# SYSCTRL_PADCONF_CORE register map
Vendor: Texas Instruments
Peripheral module from a debugger description file (folder omap4460).
Registers are 32-bit, access per field, reset 0x10F010F unless marked. A register's access mark holds for its fields unless they carry their own. Offsets are as the file gives them; lines under a group give offsets from that group; [hi:lo] are bit positions; {n}, {i} and the like mark numbered series; 'fields as' and 'values as' point back to an identical list; <NAME> marks a mode.

## SYSCTRL_PADCONF_CORE (part 1 of 10)
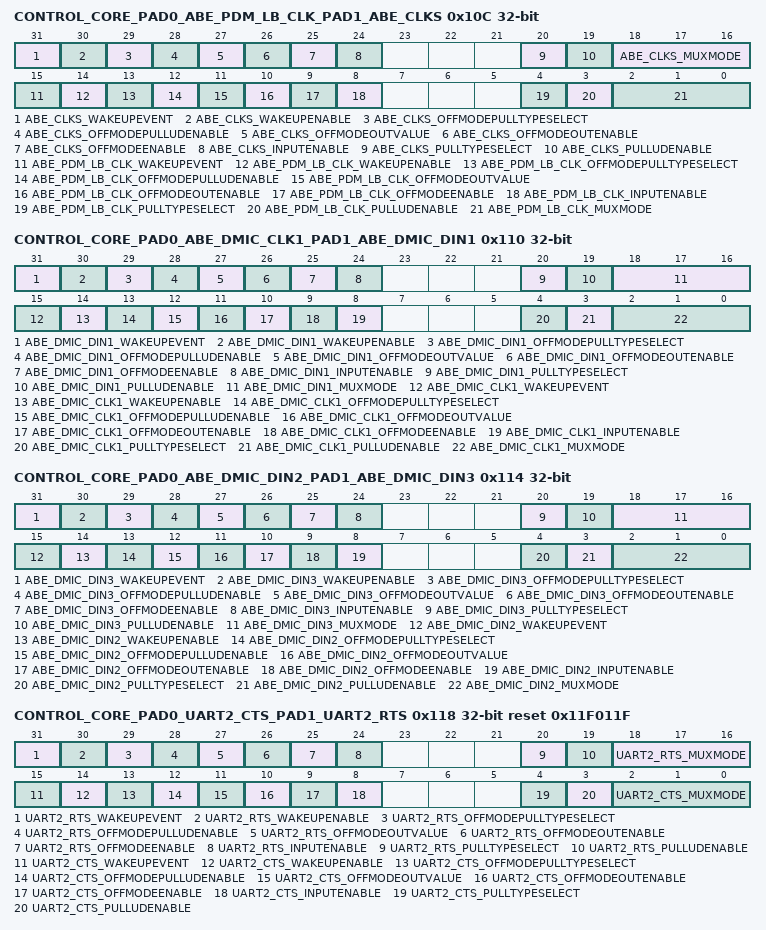
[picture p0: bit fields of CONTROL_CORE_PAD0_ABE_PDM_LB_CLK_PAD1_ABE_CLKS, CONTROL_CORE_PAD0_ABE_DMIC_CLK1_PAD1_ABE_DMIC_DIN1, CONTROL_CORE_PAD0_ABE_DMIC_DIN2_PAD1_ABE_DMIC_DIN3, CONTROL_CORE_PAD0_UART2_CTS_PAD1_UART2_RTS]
0x10C CONTROL_CORE_PAD0_ABE_PDM_LB_CLK_PAD1_ABE_CLKS — Register control for Pads abe_pdm_lb_clk and abe_clks Access conditions. Read: unrestricted, Write: unrestricted
  [31] ABE_CLKS_WAKEUPEVENT ro — Pad_x wake-up event status latched in the IO
    0=ABE_CLKS_WAKEUPEVENT_0_r (No wake-up event occurred); 1=ABE_CLKS_WAKEUPEVENT_1_r (A wake-up event occurred)
  [30] ABE_CLKS_WAKEUPENABLE rw — Input pad wake-up enable (and OFF mode input enable value)
    0=wake-up detection is disabled; 1=wake-up detection is enabled
  [29] ABE_CLKS_OFFMODEPULLTYPESELECT rw — OffMode mode pullup/down selection for pad abe_clks
    0=Offmode pulldown selected; 1=Offmode pullup selected
  [28] ABE_CLKS_OFFMODEPULLUDENABLE rw — OffMode mode pullup/down enable for pad abe_clks
    0=Offmode pullup/down disabled; 1=Offmode pullup/down enabled
  [27] ABE_CLKS_OFFMODEOUTVALUE rw — OffMode mode output value for pad abe_clks
    0=Set value at 0; 1=Set value at 1
  [26] ABE_CLKS_OFFMODEOUTENABLE rw — OffMode mode output enable value for pad abe_clks. This is an active low signal
    0=Output enable; 1=Output disable
  [25] ABE_CLKS_OFFMODEENABLE rw — OffMode mode override control for pad abe_clks
    0=I/O state keeps its previous state when OFF mode is active; 1=I/O state is forced to OFF mode value when OFF mode is active
  [24] ABE_CLKS_INPUTENABLE rw — Input enable value for pad abe_clks
    0=Input buffer of I/O cell is disabled; 1=Input buffer of I/O cell is enabled
  [20] ABE_CLKS_PULLTYPESELECT rw — pullup/down selection for pad abe_clks
    0=pulldown selected; 1=pullup selected
  [19] ABE_CLKS_PULLUDENABLE rw — pullup/down enable for pad abe_clks
    0=pullup/down disabled; 1=pullup/down enabled
  [18:16] ABE_CLKS_MUXMODE rw — Functional multiplexing selection for pad abe_clks
    0=Select abe_clks; 3=Select gpio_118; 7=Select safe_mode
  [15] ABE_PDM_LB_CLK_WAKEUPEVENT ro — Pad_x wake-up event status latched in the IO
    0=ABE_PDM_LB_CLK_WAKEUPEVENT_0_r (No wake-up event occurred); 1=ABE_PDM_LB_CLK_WAKEUPEVENT_1_r (A wake-up event occurred)
  [14] ABE_PDM_LB_CLK_WAKEUPENABLE rw — Input pad wake-up enable (and OFF mode input enable value)
    values as ABE_CLKS_WAKEUPENABLE
  [13] ABE_PDM_LB_CLK_OFFMODEPULLTYPESELECT rw — OffMode mode pullup/down selection for pad abe_pdm_lb_clk
    0=Offmode pulldown selected; 1=Offmode pullup selected
  [12] ABE_PDM_LB_CLK_OFFMODEPULLUDENABLE rw — OffMode mode pullup/down enable for pad abe_pdm_lb_clk
    values as ABE_CLKS_OFFMODEPULLUDENABLE
  [11] ABE_PDM_LB_CLK_OFFMODEOUTVALUE rw — OffMode mode output value for pad abe_pdm_lb_clk
    0=Set value at 0; 1=Set value at 1
  [10] ABE_PDM_LB_CLK_OFFMODEOUTENABLE rw — OffMode mode output enable value for pad abe_pdm_lb_clk. This is an active low signal
    0=Output enable; 1=Output disable
  [9] ABE_PDM_LB_CLK_OFFMODEENABLE rw — OffMode mode override control for pad abe_pdm_lb_clk
    values as ABE_CLKS_OFFMODEENABLE
  [8] ABE_PDM_LB_CLK_INPUTENABLE rw — Input enable value for pad abe_pdm_lb_clk
    values as ABE_CLKS_INPUTENABLE
  [4] ABE_PDM_LB_CLK_PULLTYPESELECT rw — pullup/down selection for pad abe_pdm_lb_clk
    0=pulldown selected; 1=pullup selected
  [3] ABE_PDM_LB_CLK_PULLUDENABLE rw — pullup/down enable for pad abe_pdm_lb_clk
    0=pullup/down disabled; 1=pullup/down enabled
  [2:0] ABE_PDM_LB_CLK_MUXMODE rw — Functional multiplexing selection for pad abe_pdm_lb_clk
    0=Select abe_pdm_lb_clk; 1=Select abe_mcbsp3_fsx; 7=Select safe_mode
0x110 CONTROL_CORE_PAD0_ABE_DMIC_CLK1_PAD1_ABE_DMIC_DIN1 — Register control for Pads abe_dmic_clk1 and abe_dmic_din1 Access conditions. Read: unrestricted, Write: unrestricted
  [31] ABE_DMIC_DIN1_WAKEUPEVENT ro — Pad_x wake-up event status latched in the IO
    0=ABE_DMIC_DIN1_WAKEUPEVENT_0_r (No wake-up event occurred); 1=ABE_DMIC_DIN1_WAKEUPEVENT_1_r (A wake-up event occurred)
  [30] ABE_DMIC_DIN1_WAKEUPENABLE rw — Input pad wake-up enable (and OFF mode input enable value)
    values as CONTROL_CORE_PAD0_ABE_PDM_LB_CLK_PAD1_ABE_CLKS.ABE_CLKS_WAKEUPENABLE
  [29] ABE_DMIC_DIN1_OFFMODEPULLTYPESELECT rw — OffMode mode pullup/down selection for pad abe_dmic_din1
    0=Offmode pulldown selected; 1=Offmode pullup selected
  [28] ABE_DMIC_DIN1_OFFMODEPULLUDENABLE rw — OffMode mode pullup/down enable for pad abe_dmic_din1
    values as CONTROL_CORE_PAD0_ABE_PDM_LB_CLK_PAD1_ABE_CLKS.ABE_CLKS_OFFMODEPULLUDENABLE
  [27] ABE_DMIC_DIN1_OFFMODEOUTVALUE rw — OffMode mode output value for pad abe_dmic_din1
    0=Set value at 0; 1=Set value at 1
  [26] ABE_DMIC_DIN1_OFFMODEOUTENABLE rw — OffMode mode output enable value for pad abe_dmic_din1. This is an active low signal
    0=Output enable; 1=Output disable
  [25] ABE_DMIC_DIN1_OFFMODEENABLE rw — OffMode mode override control for pad abe_dmic_din1
    values as CONTROL_CORE_PAD0_ABE_PDM_LB_CLK_PAD1_ABE_CLKS.ABE_CLKS_OFFMODEENABLE
  [24] ABE_DMIC_DIN1_INPUTENABLE rw — Input enable value for pad abe_dmic_din1
    values as CONTROL_CORE_PAD0_ABE_PDM_LB_CLK_PAD1_ABE_CLKS.ABE_CLKS_INPUTENABLE
  [20] ABE_DMIC_DIN1_PULLTYPESELECT rw — pullup/down selection for pad abe_dmic_din1
    0=pulldown selected; 1=pullup selected
  [19] ABE_DMIC_DIN1_PULLUDENABLE rw — pullup/down enable for pad abe_dmic_din1
    0=pullup/down disabled; 1=pullup/down enabled
  [18:16] ABE_DMIC_DIN1_MUXMODE rw — Functional multiplexing selection for pad abe_dmic_din1
    0=Select abe_dmic_din1; 3=Select gpio_120; 4=Select usbb2_mm_txdat; 5=Select uart4_rts; 7=Select safe_mode
  [15] ABE_DMIC_CLK1_WAKEUPEVENT ro — Pad_x wake-up event status latched in the IO
    0=ABE_DMIC_CLK1_WAKEUPEVENT_0_r (No wake-up event occurred); 1=ABE_DMIC_CLK1_WAKEUPEVENT_1_r (A wake-up event occurred)
  [14] ABE_DMIC_CLK1_WAKEUPENABLE rw — Input pad wake-up enable (and OFF mode input enable value)
    values as CONTROL_CORE_PAD0_ABE_PDM_LB_CLK_PAD1_ABE_CLKS.ABE_CLKS_WAKEUPENABLE
  [13] ABE_DMIC_CLK1_OFFMODEPULLTYPESELECT rw — OffMode mode pullup/down selection for pad abe_dmic_clk1
    0=Offmode pulldown selected; 1=Offmode pullup selected
  [12] ABE_DMIC_CLK1_OFFMODEPULLUDENABLE rw — OffMode mode pullup/down enable for pad abe_dmic_clk1
    values as CONTROL_CORE_PAD0_ABE_PDM_LB_CLK_PAD1_ABE_CLKS.ABE_CLKS_OFFMODEPULLUDENABLE
  [11] ABE_DMIC_CLK1_OFFMODEOUTVALUE rw — OffMode mode output value for pad abe_dmic_clk1
    0=Set value at 0; 1=Set value at 1
  [10] ABE_DMIC_CLK1_OFFMODEOUTENABLE rw — OffMode mode output enable value for pad abe_dmic_clk1. This is an active low signal
    0=Output enable; 1=Output disable
  [9] ABE_DMIC_CLK1_OFFMODEENABLE rw — OffMode mode override control for pad abe_dmic_clk1
    values as CONTROL_CORE_PAD0_ABE_PDM_LB_CLK_PAD1_ABE_CLKS.ABE_CLKS_OFFMODEENABLE
  [8] ABE_DMIC_CLK1_INPUTENABLE rw — Input enable value for pad abe_dmic_clk1
    values as CONTROL_CORE_PAD0_ABE_PDM_LB_CLK_PAD1_ABE_CLKS.ABE_CLKS_INPUTENABLE
  [4] ABE_DMIC_CLK1_PULLTYPESELECT rw — pullup/down selection for pad abe_dmic_clk1
    0=pulldown selected; 1=pullup selected
  [3] ABE_DMIC_CLK1_PULLUDENABLE rw — pullup/down enable for pad abe_dmic_clk1
    0=pullup/down disabled; 1=pullup/down enabled
  [2:0] ABE_DMIC_CLK1_MUXMODE rw — Functional multiplexing selection for pad abe_dmic_clk1
    0=Select abe_dmic_clk1; 3=Select gpio_119; 4=Select usbb2_mm_txse0; 5=Select uart4_cts; 7=Select safe_mode
0x114 CONTROL_CORE_PAD0_ABE_DMIC_DIN2_PAD1_ABE_DMIC_DIN3 — Register control for Pads abe_dmic_din2 and abe_dmic_din3 Access conditions. Read: unrestricted, Write: unrestricted
  [31] ABE_DMIC_DIN3_WAKEUPEVENT ro — Pad_x wake-up event status latched in the IO
    0=ABE_DMIC_DIN3_WAKEUPEVENT_0_r (No wake-up event occurred); 1=ABE_DMIC_DIN3_WAKEUPEVENT_1_r (A wake-up event occurred)
  [30] ABE_DMIC_DIN3_WAKEUPENABLE rw — Input pad wake-up enable (and OFF mode input enable value)
    values as CONTROL_CORE_PAD0_ABE_PDM_LB_CLK_PAD1_ABE_CLKS.ABE_CLKS_WAKEUPENABLE
  [29] ABE_DMIC_DIN3_OFFMODEPULLTYPESELECT rw — OffMode mode pullup/down selection for pad abe_dmic_din3
    0=Offmode pulldown selected; 1=Offmode pullup selected
  [28] ABE_DMIC_DIN3_OFFMODEPULLUDENABLE rw — OffMode mode pullup/down enable for pad abe_dmic_din3
    values as CONTROL_CORE_PAD0_ABE_PDM_LB_CLK_PAD1_ABE_CLKS.ABE_CLKS_OFFMODEPULLUDENABLE
  [27] ABE_DMIC_DIN3_OFFMODEOUTVALUE rw — OffMode mode output value for pad abe_dmic_din3
    0=Set value at 0; 1=Set value at 1
  [26] ABE_DMIC_DIN3_OFFMODEOUTENABLE rw — OffMode mode output enable value for pad abe_dmic_din3. This is an active low signal
    0=Output enable; 1=Output disable
  [25] ABE_DMIC_DIN3_OFFMODEENABLE rw — OffMode mode override control for pad abe_dmic_din3
    values as CONTROL_CORE_PAD0_ABE_PDM_LB_CLK_PAD1_ABE_CLKS.ABE_CLKS_OFFMODEENABLE
  [24] ABE_DMIC_DIN3_INPUTENABLE rw — Input enable value for pad abe_dmic_din3
    values as CONTROL_CORE_PAD0_ABE_PDM_LB_CLK_PAD1_ABE_CLKS.ABE_CLKS_INPUTENABLE
  [20] ABE_DMIC_DIN3_PULLTYPESELECT rw — pullup/down selection for pad abe_dmic_din3
    0=pulldown selected; 1=pullup selected
  [19] ABE_DMIC_DIN3_PULLUDENABLE rw — pullup/down enable for pad abe_dmic_din3
    0=pullup/down disabled; 1=pullup/down enabled
  [18:16] ABE_DMIC_DIN3_MUXMODE rw — Functional multiplexing selection for pad abe_dmic_din3
    0=Select abe_dmic_din3; 1=Select slimbus2_data; 2=Select abe_dmic_clk2; 3=Select gpio_122; 5=Select dmtimer9_pwm_evt; 7=Select safe_mode
  [15] ABE_DMIC_DIN2_WAKEUPEVENT ro — Pad_x wake-up event status latched in the IO
    0=ABE_DMIC_DIN2_WAKEUPEVENT_0_r (No wake-up event occurred); 1=ABE_DMIC_DIN2_WAKEUPEVENT_1_r (A wake-up event occurred)
  [14] ABE_DMIC_DIN2_WAKEUPENABLE rw — Input pad wake-up enable (and OFF mode input enable value)
    values as CONTROL_CORE_PAD0_ABE_PDM_LB_CLK_PAD1_ABE_CLKS.ABE_CLKS_WAKEUPENABLE
  [13] ABE_DMIC_DIN2_OFFMODEPULLTYPESELECT rw — OffMode mode pullup/down selection for pad abe_dmic_din2
    0=Offmode pulldown selected; 1=Offmode pullup selected
  [12] ABE_DMIC_DIN2_OFFMODEPULLUDENABLE rw — OffMode mode pullup/down enable for pad abe_dmic_din2
    values as CONTROL_CORE_PAD0_ABE_PDM_LB_CLK_PAD1_ABE_CLKS.ABE_CLKS_OFFMODEPULLUDENABLE
  [11] ABE_DMIC_DIN2_OFFMODEOUTVALUE rw — OffMode mode output value for pad abe_dmic_din2
    0=Set value at 0; 1=Set value at 1
  [10] ABE_DMIC_DIN2_OFFMODEOUTENABLE rw — OffMode mode output enable value for pad abe_dmic_din2. This is an active low signal
    0=Output enable; 1=Output disable
  [9] ABE_DMIC_DIN2_OFFMODEENABLE rw — OffMode mode override control for pad abe_dmic_din2
    values as CONTROL_CORE_PAD0_ABE_PDM_LB_CLK_PAD1_ABE_CLKS.ABE_CLKS_OFFMODEENABLE
  [8] ABE_DMIC_DIN2_INPUTENABLE rw — Input enable value for pad abe_dmic_din2
    values as CONTROL_CORE_PAD0_ABE_PDM_LB_CLK_PAD1_ABE_CLKS.ABE_CLKS_INPUTENABLE
  [4] ABE_DMIC_DIN2_PULLTYPESELECT rw — pullup/down selection for pad abe_dmic_din2
    0=pulldown selected; 1=pullup selected
  [3] ABE_DMIC_DIN2_PULLUDENABLE rw — pullup/down enable for pad abe_dmic_din2
    0=pullup/down disabled; 1=pullup/down enabled
  [2:0] ABE_DMIC_DIN2_MUXMODE rw — Functional multiplexing selection for pad abe_dmic_din2
    0=Select abe_dmic_din2; 1=Select slimbus2_clock; 2=Select abe_mcasp_axr; 3=Select gpio_121; 5=Select dmtimer11_pwm_evt; 7=Select safe_mode
0x118 CONTROL_CORE_PAD0_UART2_CTS_PAD1_UART2_RTS reset 0x11F011F — Register control for Pads uart2_cts and uart2_rts Access conditions. Read: unrestricted, Write: unrestricted
  [31] UART2_RTS_WAKEUPEVENT ro — Pad_x wake-up event status latched in the IO
    0=UART2_RTS_WAKEUPEVENT_0_r (No wake-up event occurred); 1=UART2_RTS_WAKEUPEVENT_1_r (A wake-up event occurred)
  [30] UART2_RTS_WAKEUPENABLE rw — Input pad wake-up enable (and OFF mode input enable value)
    values as CONTROL_CORE_PAD0_ABE_PDM_LB_CLK_PAD1_ABE_CLKS.ABE_CLKS_WAKEUPENABLE
  [29] UART2_RTS_OFFMODEPULLTYPESELECT rw — OffMode mode pullup/down selection for pad uart2_rts
    0=Offmode pulldown selected; 1=Offmode pullup selected
  [28] UART2_RTS_OFFMODEPULLUDENABLE rw — OffMode mode pullup/down enable for pad uart2_rts
    values as CONTROL_CORE_PAD0_ABE_PDM_LB_CLK_PAD1_ABE_CLKS.ABE_CLKS_OFFMODEPULLUDENABLE
  [27] UART2_RTS_OFFMODEOUTVALUE rw — OffMode mode output value for pad uart2_rts
    0=Set value at 0; 1=Set value at 1
  [26] UART2_RTS_OFFMODEOUTENABLE rw — OffMode mode output enable value for pad uart2_rts. This is an active low signal
    0=Output enable; 1=Output disable
  [25] UART2_RTS_OFFMODEENABLE rw — OffMode mode override control for pad uart2_rts
    values as CONTROL_CORE_PAD0_ABE_PDM_LB_CLK_PAD1_ABE_CLKS.ABE_CLKS_OFFMODEENABLE
  [24] UART2_RTS_INPUTENABLE rw — Input enable value for pad uart2_rts
    values as CONTROL_CORE_PAD0_ABE_PDM_LB_CLK_PAD1_ABE_CLKS.ABE_CLKS_INPUTENABLE
  [20] UART2_RTS_PULLTYPESELECT rw — pullup/down selection for pad uart2_rts
    0=pulldown selected; 1=pullup selected
  [19] UART2_RTS_PULLUDENABLE rw — pullup/down enable for pad uart2_rts
    0=pullup/down disabled; 1=pullup/down enabled
  [18:16] UART2_RTS_MUXMODE rw — Functional multiplexing selection for pad uart2_rts
    0=Select uart2_rts; 1=Select sdmmc3_cmd; 3=Select gpio_124; 7=Select safe_mode
  [15] UART2_CTS_WAKEUPEVENT ro — Pad_x wake-up event status latched in the IO
    0=UART2_CTS_WAKEUPEVENT_0_r (No wake-up event occurred); 1=UART2_CTS_WAKEUPEVENT_1_r (A wake-up event occurred)
  [14] UART2_CTS_WAKEUPENABLE rw — Input pad wake-up enable (and OFF mode input enable value)
    values as CONTROL_CORE_PAD0_ABE_PDM_LB_CLK_PAD1_ABE_CLKS.ABE_CLKS_WAKEUPENABLE
  [13] UART2_CTS_OFFMODEPULLTYPESELECT rw — OffMode mode pullup/down selection for pad uart2_cts
    0=Offmode pulldown selected; 1=Offmode pullup selected
  [12] UART2_CTS_OFFMODEPULLUDENABLE rw — OffMode mode pullup/down enable for pad uart2_cts
    values as CONTROL_CORE_PAD0_ABE_PDM_LB_CLK_PAD1_ABE_CLKS.ABE_CLKS_OFFMODEPULLUDENABLE
  [11] UART2_CTS_OFFMODEOUTVALUE rw — OffMode mode output value for pad uart2_cts
    0=Set value at 0; 1=Set value at 1
  [10] UART2_CTS_OFFMODEOUTENABLE rw — OffMode mode output enable value for pad uart2_cts. This is an active low signal
    0=Output enable; 1=Output disable
  [9] UART2_CTS_OFFMODEENABLE rw — OffMode mode override control for pad uart2_cts
    values as CONTROL_CORE_PAD0_ABE_PDM_LB_CLK_PAD1_ABE_CLKS.ABE_CLKS_OFFMODEENABLE
  [8] UART2_CTS_INPUTENABLE rw — Input enable value for pad uart2_cts
    values as CONTROL_CORE_PAD0_ABE_PDM_LB_CLK_PAD1_ABE_CLKS.ABE_CLKS_INPUTENABLE
  [4] UART2_CTS_PULLTYPESELECT rw — pullup/down selection for pad uart2_cts
    0=pulldown selected; 1=pullup selected
  [3] UART2_CTS_PULLUDENABLE rw — pullup/down enable for pad uart2_cts
    0=pullup/down disabled; 1=pullup/down enabled
  [2:0] UART2_CTS_MUXMODE rw — Functional multiplexing selection for pad uart2_cts
    0=Select uart2_cts; 1=Select sdmmc3_clk; 3=Select gpio_123; 7=Select safe_mode
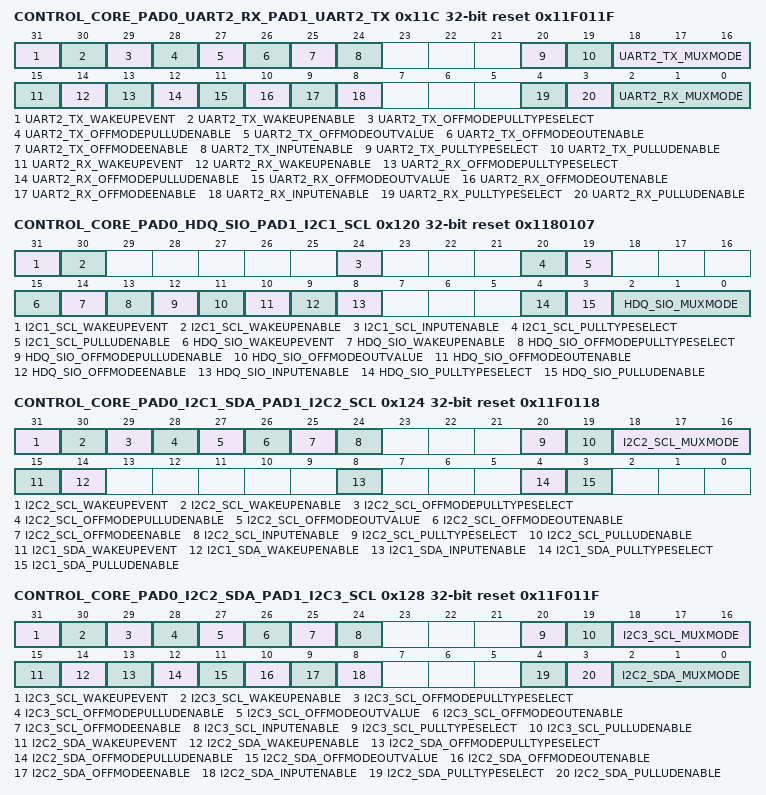
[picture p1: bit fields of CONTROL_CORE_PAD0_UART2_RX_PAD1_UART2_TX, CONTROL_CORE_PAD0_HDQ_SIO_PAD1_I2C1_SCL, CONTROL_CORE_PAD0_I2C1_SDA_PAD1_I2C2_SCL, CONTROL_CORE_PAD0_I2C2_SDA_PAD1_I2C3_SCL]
0x11C CONTROL_CORE_PAD0_UART2_RX_PAD1_UART2_TX reset 0x11F011F — Register control for Pads uart2_rx and uart2_tx Access conditions. Read: unrestricted, Write: unrestricted
  [31] UART2_TX_WAKEUPEVENT ro — Pad_x wake-up event status latched in the IO
    0=UART2_TX_WAKEUPEVENT_0_r (No wake-up event occurred); 1=UART2_TX_WAKEUPEVENT_1_r (A wake-up event occurred)
  [30] UART2_TX_WAKEUPENABLE rw — Input pad wake-up enable (and OFF mode input enable value)
    values as CONTROL_CORE_PAD0_ABE_PDM_LB_CLK_PAD1_ABE_CLKS.ABE_CLKS_WAKEUPENABLE
  [29] UART2_TX_OFFMODEPULLTYPESELECT rw — OffMode mode pullup/down selection for pad uart2_tx
    0=Offmode pulldown selected; 1=Offmode pullup selected
  [28] UART2_TX_OFFMODEPULLUDENABLE rw — OffMode mode pullup/down enable for pad uart2_tx
    values as CONTROL_CORE_PAD0_ABE_PDM_LB_CLK_PAD1_ABE_CLKS.ABE_CLKS_OFFMODEPULLUDENABLE
  [27] UART2_TX_OFFMODEOUTVALUE rw — OffMode mode output value for pad uart2_tx
    0=Set value at 0; 1=Set value at 1
  [26] UART2_TX_OFFMODEOUTENABLE rw — OffMode mode output enable value for pad uart2_tx. This is an active low signal
    0=Output enable; 1=Output disable
  [25] UART2_TX_OFFMODEENABLE rw — OffMode mode override control for pad uart2_tx
    values as CONTROL_CORE_PAD0_ABE_PDM_LB_CLK_PAD1_ABE_CLKS.ABE_CLKS_OFFMODEENABLE
  [24] UART2_TX_INPUTENABLE rw — Input enable value for pad uart2_tx
    values as CONTROL_CORE_PAD0_ABE_PDM_LB_CLK_PAD1_ABE_CLKS.ABE_CLKS_INPUTENABLE
  [20] UART2_TX_PULLTYPESELECT rw — pullup/down selection for pad uart2_tx
    0=pulldown selected; 1=pullup selected
  [19] UART2_TX_PULLUDENABLE rw — pullup/down enable for pad uart2_tx
    0=pullup/down disabled; 1=pullup/down enabled
  [18:16] UART2_TX_MUXMODE rw — Functional multiplexing selection for pad uart2_tx
    0=Select uart2_tx; 1=Select sdmmc3_dat1; 3=Select gpio_126; 7=Select safe_mode
  [15] UART2_RX_WAKEUPEVENT ro — Pad_x wake-up event status latched in the IO
    0=UART2_RX_WAKEUPEVENT_0_r (No wake-up event occurred); 1=UART2_RX_WAKEUPEVENT_1_r (A wake-up event occurred)
  [14] UART2_RX_WAKEUPENABLE rw — Input pad wake-up enable (and OFF mode input enable value)
    values as CONTROL_CORE_PAD0_ABE_PDM_LB_CLK_PAD1_ABE_CLKS.ABE_CLKS_WAKEUPENABLE
  [13] UART2_RX_OFFMODEPULLTYPESELECT rw — OffMode mode pullup/down selection for pad uart2_rx
    0=Offmode pulldown selected; 1=Offmode pullup selected
  [12] UART2_RX_OFFMODEPULLUDENABLE rw — OffMode mode pullup/down enable for pad uart2_rx
    values as CONTROL_CORE_PAD0_ABE_PDM_LB_CLK_PAD1_ABE_CLKS.ABE_CLKS_OFFMODEPULLUDENABLE
  [11] UART2_RX_OFFMODEOUTVALUE rw — OffMode mode output value for pad uart2_rx
    0=Set value at 0; 1=Set value at 1
  [10] UART2_RX_OFFMODEOUTENABLE rw — OffMode mode output enable value for pad uart2_rx. This is an active low signal
    0=Output enable; 1=Output disable
  [9] UART2_RX_OFFMODEENABLE rw — OffMode mode override control for pad uart2_rx
    values as CONTROL_CORE_PAD0_ABE_PDM_LB_CLK_PAD1_ABE_CLKS.ABE_CLKS_OFFMODEENABLE
  [8] UART2_RX_INPUTENABLE rw — Input enable value for pad uart2_rx
    values as CONTROL_CORE_PAD0_ABE_PDM_LB_CLK_PAD1_ABE_CLKS.ABE_CLKS_INPUTENABLE
  [4] UART2_RX_PULLTYPESELECT rw — pullup/down selection for pad uart2_rx
    0=pulldown selected; 1=pullup selected
  [3] UART2_RX_PULLUDENABLE rw — pullup/down enable for pad uart2_rx
    0=pullup/down disabled; 1=pullup/down enabled
  [2:0] UART2_RX_MUXMODE rw — Functional multiplexing selection for pad uart2_rx
    0=Select uart2_rx; 1=Select sdmmc3_dat0; 3=Select gpio_125; 7=Select safe_mode
0x120 CONTROL_CORE_PAD0_HDQ_SIO_PAD1_I2C1_SCL reset 0x1180107 — Register control for Pads hdq_sio and i2c1_scl Access conditions. Read: unrestricted, Write: unrestricted
  [31] I2C1_SCL_WAKEUPEVENT ro — Pad_x wake-up event status latched in the IO
    0=I2C1_SCL_WAKEUPEVENT_0_r (No wake-up event occurred); 1=I2C1_SCL_WAKEUPEVENT_1_r (A wake-up event occurred)
  [30] I2C1_SCL_WAKEUPENABLE rw — Input pad wake-up enable (and OFF mode input enable value)
    0=Wake-up detection is disabled; 1=Wake-up detection is enabled
  [24] I2C1_SCL_INPUTENABLE rw — Input enable value for pad i2c1_scl
    values as CONTROL_CORE_PAD0_ABE_PDM_LB_CLK_PAD1_ABE_CLKS.ABE_CLKS_INPUTENABLE
  [20] I2C1_SCL_PULLTYPESELECT rw — pullup/down selection for pad i2c1_scl
    0=Pulldown selected; 1=Pullup selected
  [19] I2C1_SCL_PULLUDENABLE rw — pullup/down enable for pad i2c1_scl
    0=Pullup/down disabled; 1=Pullup/down enabled
  [15] HDQ_SIO_WAKEUPEVENT ro — Pad_x wake-up event status latched in the IO
    0=HDQ_SIO_WAKEUPEVENT_0_r (No wake-up event occurred); 1=HDQ_SIO_WAKEUPEVENT_1_r (A wake-up event occurred)
  [14] HDQ_SIO_WAKEUPENABLE rw — Input pad wake-up enable (and OFF mode input enable value)
    values as I2C1_SCL_WAKEUPENABLE
  [13] HDQ_SIO_OFFMODEPULLTYPESELECT rw — OffMode mode pullup/pulldown selection for pad hdq_sio
    0=Offmode pulldown selected; 1=Offmode pullup selected
  [12] HDQ_SIO_OFFMODEPULLUDENABLE rw — OffMode mode pullup/down enable for pad hdq_sio
    values as CONTROL_CORE_PAD0_ABE_PDM_LB_CLK_PAD1_ABE_CLKS.ABE_CLKS_OFFMODEPULLUDENABLE
  [11] HDQ_SIO_OFFMODEOUTVALUE rw — OffMode mode output value for pad hdq_sio
    0=Set value at 0; 1=Set value at 1
  [10] HDQ_SIO_OFFMODEOUTENABLE rw — OffMode mode output enable value for pad hdq_sio. This is an active low signal
    0=Output enable; 1=Output disable
  [9] HDQ_SIO_OFFMODEENABLE rw — OffMode mode override control for pad hdq_sio
    values as CONTROL_CORE_PAD0_ABE_PDM_LB_CLK_PAD1_ABE_CLKS.ABE_CLKS_OFFMODEENABLE
  [8] HDQ_SIO_INPUTENABLE rw — Input enable value for pad hdq_sio
    values as CONTROL_CORE_PAD0_ABE_PDM_LB_CLK_PAD1_ABE_CLKS.ABE_CLKS_INPUTENABLE
  [4] HDQ_SIO_PULLTYPESELECT rw — Pullup/down selection for pad hdq_sio
    0=Pulldown selected; 1=Pullip selected
  [3] HDQ_SIO_PULLUDENABLE rw — Pullup/down enable for pad hdq_sio
    0=Pullup/down disabled; 1=Pullup/down enabled
  [2:0] HDQ_SIO_MUXMODE rw — Functional multiplexing selection for pad hdq_sio
    0=Select hdq_sio; 1=Select i2c3_sccb; 2=Select i2c2_sccb; 3=Select gpio_127; 7=Select safe_mode
0x124 CONTROL_CORE_PAD0_I2C1_SDA_PAD1_I2C2_SCL reset 0x11F0118 — Register control for Pads i2c1_sda and i2c2_scl Access conditions. Read: unrestricted, Write: unrestricted
  [31] I2C2_SCL_WAKEUPEVENT ro — Pad_x wake-up event status latched in the IO
    0=I2C2_SCL_WAKEUPEVENT_0_r (No wake-up event occurred); 1=I2C2_SCL_WAKEUPEVENT_1_r (A wake-up event occurred)
  [30] I2C2_SCL_WAKEUPENABLE rw — Input pad wake-up enable (and OFF mode input enable value)
    values as CONTROL_CORE_PAD0_ABE_PDM_LB_CLK_PAD1_ABE_CLKS.ABE_CLKS_WAKEUPENABLE
  [29] I2C2_SCL_OFFMODEPULLTYPESELECT rw — OffMode mode pullup/down selection for pad i2c2_scl
    0=Offmode pulldown selected; 1=Offmode pullup selected
  [28] I2C2_SCL_OFFMODEPULLUDENABLE rw — OffMode mode pullup/down enable for pad i2c2_scl
    values as CONTROL_CORE_PAD0_ABE_PDM_LB_CLK_PAD1_ABE_CLKS.ABE_CLKS_OFFMODEPULLUDENABLE
  [27] I2C2_SCL_OFFMODEOUTVALUE rw — OffMode mode output value for pad i2c2_scl
    0=Set value at 0; 1=Set value at 1
  [26] I2C2_SCL_OFFMODEOUTENABLE rw — OffMode mode output enable value for pad i2c2_scl. This is an active low signal
    0=Output enable; 1=Output disable
  [25] I2C2_SCL_OFFMODEENABLE rw — OffMode mode override control for pad i2c2_scl
    values as CONTROL_CORE_PAD0_ABE_PDM_LB_CLK_PAD1_ABE_CLKS.ABE_CLKS_OFFMODEENABLE
  [24] I2C2_SCL_INPUTENABLE rw — Input enable value for pad i2c2_scl
    values as CONTROL_CORE_PAD0_ABE_PDM_LB_CLK_PAD1_ABE_CLKS.ABE_CLKS_INPUTENABLE
  [20] I2C2_SCL_PULLTYPESELECT rw — pullup/down selection for pad i2c2_scl
    0=pulldown selected; 1=pullup selected
  [19] I2C2_SCL_PULLUDENABLE rw — pullup/down enable for pad i2c2_scl
    0=pullup/down disabled; 1=pullup/down enabled
  [18:16] I2C2_SCL_MUXMODE rw — Functional multiplexing selection for pad i2c2_scl
    0=Select i2c2_scl; 1=Select uart1_rx; 3=Select gpio_128; 7=Select safe_mode
  [15] I2C1_SDA_WAKEUPEVENT ro — Pad_x wake-up event status latched in the IO
    0=I2C1_SDA_WAKEUPEVENT_0_r (No wake-up event occurred); 1=I2C1_SDA_WAKEUPEVENT_1_r (A wake-up event occurred)
  [14] I2C1_SDA_WAKEUPENABLE rw — Input pad wake-up enable (and OFF mode input enable value)
    values as CONTROL_CORE_PAD0_ABE_PDM_LB_CLK_PAD1_ABE_CLKS.ABE_CLKS_WAKEUPENABLE
  [8] I2C1_SDA_INPUTENABLE rw — Input enable value for pad i2c1_sda
    values as CONTROL_CORE_PAD0_ABE_PDM_LB_CLK_PAD1_ABE_CLKS.ABE_CLKS_INPUTENABLE
  [4] I2C1_SDA_PULLTYPESELECT rw — pullup/down selection for pad i2c1_sda
    0=pulldown selected; 1=pullup selected
  [3] I2C1_SDA_PULLUDENABLE rw — pullup/down enable for pad i2c1_sda
    0=pullup/down disabled; 1=pullup/down enabled
0x128 CONTROL_CORE_PAD0_I2C2_SDA_PAD1_I2C3_SCL reset 0x11F011F — Register control for Pads i2c2_sda and i2c3_scl Access conditions. Read: unrestricted, Write: unrestricted
  [31] I2C3_SCL_WAKEUPEVENT ro — Pad_x wake-up event status latched in the IO
    0=I2C3_SCL_WAKEUPEVENT_0_r (No wake-up event occurred); 1=I2C3_SCL_WAKEUPEVENT_1_r (A wake-up event occurred)
  [30] I2C3_SCL_WAKEUPENABLE rw — Input pad wake-up enable (and OFF mode input enable value)
    values as CONTROL_CORE_PAD0_ABE_PDM_LB_CLK_PAD1_ABE_CLKS.ABE_CLKS_WAKEUPENABLE
  [29] I2C3_SCL_OFFMODEPULLTYPESELECT rw — OffMode mode pullup/down selection for pad i2c3_scl
    0=Offmode pulldown selected; 1=Offmode pullup selected
  [28] I2C3_SCL_OFFMODEPULLUDENABLE rw — OffMode mode pullup/down enable for pad i2c3_scl
    values as CONTROL_CORE_PAD0_ABE_PDM_LB_CLK_PAD1_ABE_CLKS.ABE_CLKS_OFFMODEPULLUDENABLE
  [27] I2C3_SCL_OFFMODEOUTVALUE rw — OffMode mode output value for pad i2c3_scl
    0=Set value at 0; 1=Set value at 1
  [26] I2C3_SCL_OFFMODEOUTENABLE rw — OffMode mode output enable value for pad i2c3_scl. This is an active low signal
    0=Output enable; 1=Output disable
  [25] I2C3_SCL_OFFMODEENABLE rw — OffMode mode override control for pad i2c3_scl
    values as CONTROL_CORE_PAD0_ABE_PDM_LB_CLK_PAD1_ABE_CLKS.ABE_CLKS_OFFMODEENABLE
  [24] I2C3_SCL_INPUTENABLE rw — Input enable value for pad i2c3_scl
    values as CONTROL_CORE_PAD0_ABE_PDM_LB_CLK_PAD1_ABE_CLKS.ABE_CLKS_INPUTENABLE
  [20] I2C3_SCL_PULLTYPESELECT rw — pullup/down selection for pad i2c3_scl
    0=pulldown selected; 1=pullup selected
  [19] I2C3_SCL_PULLUDENABLE rw — pullup/down enable for pad i2c3_scl
    0=pullup/down disabled; 1=pullup/down enabled
  [18:16] I2C3_SCL_MUXMODE rw — Functional multiplexing selection for pad i2c3_scl
    0=Select i2c3_scl; 3=Select gpio_130; 7=Select safe_mode
  [15] I2C2_SDA_WAKEUPEVENT ro — Pad_x wake-up event status latched in the IO
    0=I2C2_SDA_WAKEUPEVENT_0_r (No wake-up event occurred); 1=I2C2_SDA_WAKEUPEVENT_1_r (A wake-up event occurred)
  [14] I2C2_SDA_WAKEUPENABLE rw — Input pad wake-up enable (and OFF mode input enable value)
    values as CONTROL_CORE_PAD0_ABE_PDM_LB_CLK_PAD1_ABE_CLKS.ABE_CLKS_WAKEUPENABLE
  [13] I2C2_SDA_OFFMODEPULLTYPESELECT rw — OffMode mode pullup/down selection for pad i2c2_sda
    0=Offmode pulldown selected; 1=Offmode pullup selected
  [12] I2C2_SDA_OFFMODEPULLUDENABLE rw — OffMode mode pullup/down enable for pad i2c2_sda
    values as CONTROL_CORE_PAD0_ABE_PDM_LB_CLK_PAD1_ABE_CLKS.ABE_CLKS_OFFMODEPULLUDENABLE
  [11] I2C2_SDA_OFFMODEOUTVALUE rw — OffMode mode output value for pad i2c2_sda
    0=Set value at 0; 1=Set value at 1
  [10] I2C2_SDA_OFFMODEOUTENABLE rw — OffMode mode output enable value for pad i2c2_sda. This is an active low signal
    0=Output enable; 1=Output disable
  [9] I2C2_SDA_OFFMODEENABLE rw — OffMode mode override control for pad i2c2_sda
    values as CONTROL_CORE_PAD0_ABE_PDM_LB_CLK_PAD1_ABE_CLKS.ABE_CLKS_OFFMODEENABLE
  [8] I2C2_SDA_INPUTENABLE rw — Input enable value for pad i2c2_sda
    values as CONTROL_CORE_PAD0_ABE_PDM_LB_CLK_PAD1_ABE_CLKS.ABE_CLKS_INPUTENABLE
  [4] I2C2_SDA_PULLTYPESELECT rw — pullup/down selection for pad i2c2_sda
    0=pulldown selected; 1=pullup selected
  [3] I2C2_SDA_PULLUDENABLE rw — pullup/down enable for pad i2c2_sda
    0=pullup/down disabled; 1=pullup/down enabled
  [2:0] I2C2_SDA_MUXMODE rw — Functional multiplexing selection for pad i2c2_sda
    0=Select i2c2_sda; 1=Select uart1_tx; 3=Select gpio_129; 7=Select safe_mode
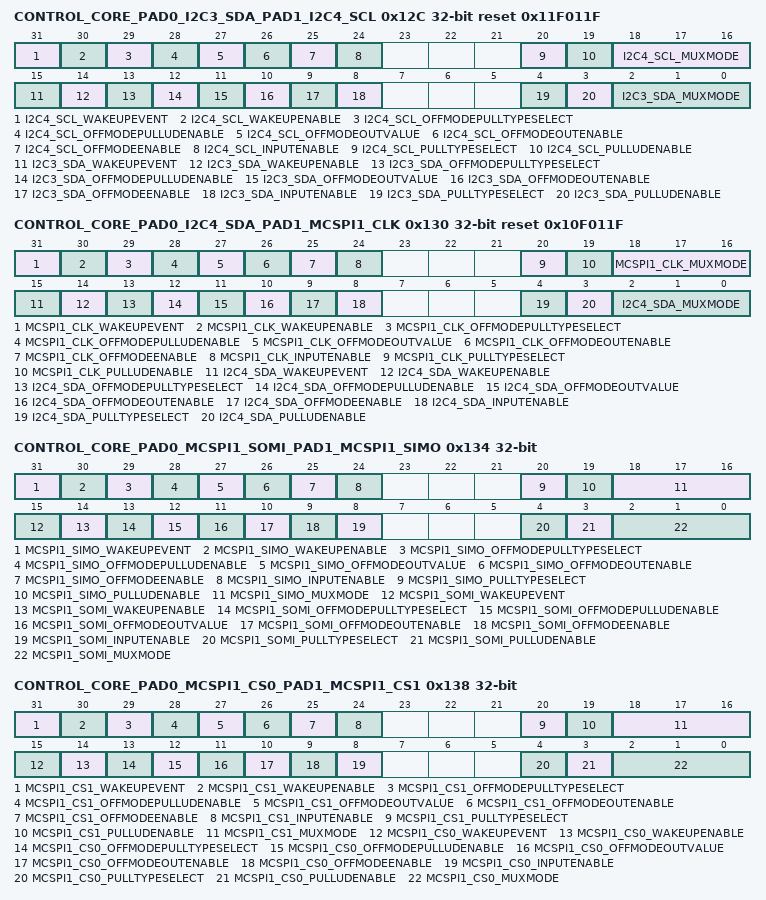
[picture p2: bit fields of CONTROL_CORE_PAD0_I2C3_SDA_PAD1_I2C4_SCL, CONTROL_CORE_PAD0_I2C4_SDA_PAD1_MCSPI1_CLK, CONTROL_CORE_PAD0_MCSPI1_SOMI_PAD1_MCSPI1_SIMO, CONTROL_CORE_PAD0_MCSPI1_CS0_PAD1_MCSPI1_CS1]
0x12C CONTROL_CORE_PAD0_I2C3_SDA_PAD1_I2C4_SCL reset 0x11F011F — Register control for Pads i2c3_sda and i2c4_scl Access conditions. Read: unrestricted, Write: unrestricted
  [31] I2C4_SCL_WAKEUPEVENT ro — Pad_x wake-up event status latched in the IO
    0=I2C4_SCL_WAKEUPEVENT_0_r (No wake-up event occurred); 1=I2C4_SCL_WAKEUPEVENT_1_r (A wake-up event occurred)
  [30] I2C4_SCL_WAKEUPENABLE rw — Input pad wake-up enable (and OFF mode input enable value)
    values as CONTROL_CORE_PAD0_ABE_PDM_LB_CLK_PAD1_ABE_CLKS.ABE_CLKS_WAKEUPENABLE
  [29] I2C4_SCL_OFFMODEPULLTYPESELECT rw — OffMode mode pullup/down selection for pad i2c4_scl
    0=Offmode pulldown selected; 1=Offmode pullup selected
  [28] I2C4_SCL_OFFMODEPULLUDENABLE rw — OffMode mode pullup/down enable for pad i2c4_scl
    values as CONTROL_CORE_PAD0_ABE_PDM_LB_CLK_PAD1_ABE_CLKS.ABE_CLKS_OFFMODEPULLUDENABLE
  [27] I2C4_SCL_OFFMODEOUTVALUE rw — OffMode mode output value for pad i2c4_scl
    0=Set value at 0; 1=Set value at 1
  [26] I2C4_SCL_OFFMODEOUTENABLE rw — OffMode mode output enable value for pad i2c4_scl. This is an active low signal
    0=Output enable; 1=Output disable
  [25] I2C4_SCL_OFFMODEENABLE rw — OffMode mode override control for pad i2c4_scl
    values as CONTROL_CORE_PAD0_ABE_PDM_LB_CLK_PAD1_ABE_CLKS.ABE_CLKS_OFFMODEENABLE
  [24] I2C4_SCL_INPUTENABLE rw — Input enable value for pad i2c4_scl
    values as CONTROL_CORE_PAD0_ABE_PDM_LB_CLK_PAD1_ABE_CLKS.ABE_CLKS_INPUTENABLE
  [20] I2C4_SCL_PULLTYPESELECT rw — pullup/down selection for pad i2c4_scl
    0=pulldown selected; 1=pullup selected
  [19] I2C4_SCL_PULLUDENABLE rw — pullup/down enable for pad i2c4_scl
    0=pullup/down disabled; 1=pullup/down enabled
  [18:16] I2C4_SCL_MUXMODE rw — Functional multiplexing selection for pad i2c4_scl
    0=Select i2c4_scl; 3=Select gpio_132; 7=Select safe_mode
  [15] I2C3_SDA_WAKEUPEVENT ro — Pad_x wake-up event status latched in the IO
    0=I2C3_SDA_WAKEUPEVENT_0_r (No wake-up event occurred); 1=I2C3_SDA_WAKEUPEVENT_1_r (A wake-up event occurred)
  [14] I2C3_SDA_WAKEUPENABLE rw — Input pad wake-up enable (and OFF mode input enable value)
    values as CONTROL_CORE_PAD0_ABE_PDM_LB_CLK_PAD1_ABE_CLKS.ABE_CLKS_WAKEUPENABLE
  [13] I2C3_SDA_OFFMODEPULLTYPESELECT rw — OffMode mode pullup/down selection for pad i2c3_sda
    0=Offmode pulldown selected; 1=Offmode pullup selected
  [12] I2C3_SDA_OFFMODEPULLUDENABLE rw — OffMode mode pullup/down enable for pad i2c3_sda
    values as CONTROL_CORE_PAD0_ABE_PDM_LB_CLK_PAD1_ABE_CLKS.ABE_CLKS_OFFMODEPULLUDENABLE
  [11] I2C3_SDA_OFFMODEOUTVALUE rw — OffMode mode output value for pad i2c3_sda
    0=Set value at 0; 1=Set value at 1
  [10] I2C3_SDA_OFFMODEOUTENABLE rw — OffMode mode output enable value for pad i2c3_sda. This is an active low signal
    0=Output enable; 1=Output disable
  [9] I2C3_SDA_OFFMODEENABLE rw — OffMode mode override control for pad i2c3_sda
    values as CONTROL_CORE_PAD0_ABE_PDM_LB_CLK_PAD1_ABE_CLKS.ABE_CLKS_OFFMODEENABLE
  [8] I2C3_SDA_INPUTENABLE rw — Input enable value for pad i2c3_sda
    values as CONTROL_CORE_PAD0_ABE_PDM_LB_CLK_PAD1_ABE_CLKS.ABE_CLKS_INPUTENABLE
  [4] I2C3_SDA_PULLTYPESELECT rw — pullup/down selection for pad i2c3_sda
    0=pulldown selected; 1=pullup selected
  [3] I2C3_SDA_PULLUDENABLE rw — pullup/down enable for pad i2c3_sda
    0=pullup/down disabled; 1=pullup/down enabled
  [2:0] I2C3_SDA_MUXMODE rw — Functional multiplexing selection for pad i2c3_sda
    0=Select i2c3_sda; 3=Select gpio_131; 7=Select safe_mode
0x130 CONTROL_CORE_PAD0_I2C4_SDA_PAD1_MCSPI1_CLK reset 0x10F011F — Register control for Pads i2c4_sda and mcspi1_clk Access conditions. Read: unrestricted, Write: unrestricted
  [31] MCSPI1_CLK_WAKEUPEVENT ro — Pad_x wake-up event status latched in the IO
    0=MCSPI1_CLK_WAKEUPEVENT_0_r (No wake-up event occurred); 1=MCSPI1_CLK_WAKEUPEVENT_1_r (A wake-up event occurred)
  [30] MCSPI1_CLK_WAKEUPENABLE rw — Input pad wake-up enable (and OFF mode input enable value)
    values as CONTROL_CORE_PAD0_ABE_PDM_LB_CLK_PAD1_ABE_CLKS.ABE_CLKS_WAKEUPENABLE
  [29] MCSPI1_CLK_OFFMODEPULLTYPESELECT rw — OffMode mode pullup/down selection for pad mcspi1_clk
    0=Offmode pulldown selected; 1=Offmode pullup selected
  [28] MCSPI1_CLK_OFFMODEPULLUDENABLE rw — OffMode mode pullup/down enable for pad mcspi1_clk
    values as CONTROL_CORE_PAD0_ABE_PDM_LB_CLK_PAD1_ABE_CLKS.ABE_CLKS_OFFMODEPULLUDENABLE
  [27] MCSPI1_CLK_OFFMODEOUTVALUE rw — OffMode mode output value for pad mcspi1_clk
    0=Set value at 0; 1=Set value at 1
  [26] MCSPI1_CLK_OFFMODEOUTENABLE rw — OffMode mode output enable value for pad mcspi1_clk. This is an active low signal
    0=Output enable; 1=Output disable
  [25] MCSPI1_CLK_OFFMODEENABLE rw — OffMode mode override control for pad mcspi1_clk
    values as CONTROL_CORE_PAD0_ABE_PDM_LB_CLK_PAD1_ABE_CLKS.ABE_CLKS_OFFMODEENABLE
  [24] MCSPI1_CLK_INPUTENABLE rw — Input enable value for pad mcspi1_clk
    values as CONTROL_CORE_PAD0_ABE_PDM_LB_CLK_PAD1_ABE_CLKS.ABE_CLKS_INPUTENABLE
  [20] MCSPI1_CLK_PULLTYPESELECT rw — pullup/down selection for pad mcspi1_clk
    0=pulldown selected; 1=pullup selected
  [19] MCSPI1_CLK_PULLUDENABLE rw — pullup/down enable for pad mcspi1_clk
    0=pullup/down disabled; 1=pullup/down enabled
  [18:16] MCSPI1_CLK_MUXMODE rw — Functional multiplexing selection for pad mcspi1_clk
    0=Select mcspi1_clk; 3=Select gpio_134; 7=Select safe_mode
  [15] I2C4_SDA_WAKEUPEVENT ro — Pad_x wake-up event status latched in the IO
    0=I2C4_SDA_WAKEUPEVENT_0_r (No wake-up event occurred); 1=I2C4_SDA_WAKEUPEVENT_1_r (A wake-up event occurred)
  [14] I2C4_SDA_WAKEUPENABLE rw — Input pad wake-up enable (and OFF mode input enable value)
    values as CONTROL_CORE_PAD0_ABE_PDM_LB_CLK_PAD1_ABE_CLKS.ABE_CLKS_WAKEUPENABLE
  [13] I2C4_SDA_OFFMODEPULLTYPESELECT rw — OffMode mode pullup/down selection for pad i2c4_sda
    0=Offmode pulldown selected; 1=Offmode pullup selected
  [12] I2C4_SDA_OFFMODEPULLUDENABLE rw — OffMode mode pullup/down enable for pad i2c4_sda
    values as CONTROL_CORE_PAD0_ABE_PDM_LB_CLK_PAD1_ABE_CLKS.ABE_CLKS_OFFMODEPULLUDENABLE
  [11] I2C4_SDA_OFFMODEOUTVALUE rw — OffMode mode output value for pad i2c4_sda
    0=Set value at 0; 1=Set value at 1
  [10] I2C4_SDA_OFFMODEOUTENABLE rw — OffMode mode output enable value for pad i2c4_sda. This is an active low signal
    0=Output enable; 1=Output disable
  [9] I2C4_SDA_OFFMODEENABLE rw — OffMode mode override control for pad i2c4_sda
    values as CONTROL_CORE_PAD0_ABE_PDM_LB_CLK_PAD1_ABE_CLKS.ABE_CLKS_OFFMODEENABLE
  [8] I2C4_SDA_INPUTENABLE rw — Input enable value for pad i2c4_sda
    values as CONTROL_CORE_PAD0_ABE_PDM_LB_CLK_PAD1_ABE_CLKS.ABE_CLKS_INPUTENABLE
  [4] I2C4_SDA_PULLTYPESELECT rw — pullup/down selection for pad i2c4_sda
    0=pulldown selected; 1=pullup selected
  [3] I2C4_SDA_PULLUDENABLE rw — pullup/down enable for pad i2c4_sda
    0=pullup/down disabled; 1=pullup/down enabled
  [2:0] I2C4_SDA_MUXMODE rw — Functional multiplexing selection for pad i2c4_sda
    0=Select i2c4_sda; 3=Select gpio_133; 7=Select safe_mode
0x134 CONTROL_CORE_PAD0_MCSPI1_SOMI_PAD1_MCSPI1_SIMO — Register control for Pads mcspi1_somi and mcspi1_simo Access conditions. Read: unrestricted, Write: unrestricted
  [31] MCSPI1_SIMO_WAKEUPEVENT ro — Pad_x wake-up event status latched in the IO
    0=MCSPI1_SIMO_WAKEUPEVENT_0_r (No wake-up event occurred); 1=MCSPI1_SIMO_WAKEUPEVENT_1_r (A wake-up event occurred)
  [30] MCSPI1_SIMO_WAKEUPENABLE rw — Input pad wake-up enable (and OFF mode input enable value)
    values as CONTROL_CORE_PAD0_ABE_PDM_LB_CLK_PAD1_ABE_CLKS.ABE_CLKS_WAKEUPENABLE
  [29] MCSPI1_SIMO_OFFMODEPULLTYPESELECT rw — OffMode mode pullup/down selection for pad mcspi1_simo
    0=Offmode pulldown selected; 1=Offmode pullup selected
  [28] MCSPI1_SIMO_OFFMODEPULLUDENABLE rw — OffMode mode pullup/down enable for pad mcspi1_simo
    values as CONTROL_CORE_PAD0_ABE_PDM_LB_CLK_PAD1_ABE_CLKS.ABE_CLKS_OFFMODEPULLUDENABLE
  [27] MCSPI1_SIMO_OFFMODEOUTVALUE rw — OffMode mode output value for pad mcspi1_simo
    0=Set value at 0; 1=Set value at 1
  [26] MCSPI1_SIMO_OFFMODEOUTENABLE rw — OffMode mode output enable value for pad mcspi1_simo. This is an active low signal
    0=Output enable; 1=Output disable
  [25] MCSPI1_SIMO_OFFMODEENABLE rw — OffMode mode override control for pad mcspi1_simo
    values as CONTROL_CORE_PAD0_ABE_PDM_LB_CLK_PAD1_ABE_CLKS.ABE_CLKS_OFFMODEENABLE
  [24] MCSPI1_SIMO_INPUTENABLE rw — Input enable value for pad mcspi1_simo
    values as CONTROL_CORE_PAD0_ABE_PDM_LB_CLK_PAD1_ABE_CLKS.ABE_CLKS_INPUTENABLE
  [20] MCSPI1_SIMO_PULLTYPESELECT rw — pullup/down selection for pad mcspi1_simo
    0=pulldown selected; 1=pullup selected
  [19] MCSPI1_SIMO_PULLUDENABLE rw — pullup/down enable for pad mcspi1_simo
    0=pullup/down disabled; 1=pullup/down enabled
  [18:16] MCSPI1_SIMO_MUXMODE rw — Functional multiplexing selection for pad mcspi1_simo
    0=Select mcspi1_simo; 3=Select gpio_136; 7=Select safe_mode
  [15] MCSPI1_SOMI_WAKEUPEVENT ro — Pad_x wake-up event status latched in the IO
    0=MCSPI1_SOMI_WAKEUPEVENT_0_r (No wake-up event occurred); 1=MCSPI1_SOMI_WAKEUPEVENT_1_r (A wake-up event occurred)
  [14] MCSPI1_SOMI_WAKEUPENABLE rw — Input pad wake-up enable (and OFF mode input enable value)
    values as CONTROL_CORE_PAD0_ABE_PDM_LB_CLK_PAD1_ABE_CLKS.ABE_CLKS_WAKEUPENABLE
  [13] MCSPI1_SOMI_OFFMODEPULLTYPESELECT rw — OffMode mode pullup/down selection for pad mcspi1_somi
    0=Offmode pulldown selected; 1=Offmode pullup selected
  [12] MCSPI1_SOMI_OFFMODEPULLUDENABLE rw — OffMode mode pullup/down enable for pad mcspi1_somi
    values as CONTROL_CORE_PAD0_ABE_PDM_LB_CLK_PAD1_ABE_CLKS.ABE_CLKS_OFFMODEPULLUDENABLE
  [11] MCSPI1_SOMI_OFFMODEOUTVALUE rw — OffMode mode output value for pad mcspi1_somi
    0=Set value at 0; 1=Set value at 1
  [10] MCSPI1_SOMI_OFFMODEOUTENABLE rw — OffMode mode output enable value for pad mcspi1_somi. This is an active low signal
    0=Output enable; 1=Output disable
  [9] MCSPI1_SOMI_OFFMODEENABLE rw — OffMode mode override control for pad mcspi1_somi
    values as CONTROL_CORE_PAD0_ABE_PDM_LB_CLK_PAD1_ABE_CLKS.ABE_CLKS_OFFMODEENABLE
  [8] MCSPI1_SOMI_INPUTENABLE rw — Input enable value for pad mcspi1_somi
    values as CONTROL_CORE_PAD0_ABE_PDM_LB_CLK_PAD1_ABE_CLKS.ABE_CLKS_INPUTENABLE
  [4] MCSPI1_SOMI_PULLTYPESELECT rw — pullup/down selection for pad mcspi1_somi
    0=pulldown selected; 1=pullup selected
  [3] MCSPI1_SOMI_PULLUDENABLE rw — pullup/down enable for pad mcspi1_somi
    0=pullup/down disabled; 1=pullup/down enabled
  [2:0] MCSPI1_SOMI_MUXMODE rw — Functional multiplexing selection for pad mcspi1_somi
    0=Select mcspi1_somi; 3=Select gpio_135; 7=Select safe_mode
0x138 CONTROL_CORE_PAD0_MCSPI1_CS0_PAD1_MCSPI1_CS1 — Register control for Pads mcspi1_cs0 and mcspi1_cs1 Access conditions. Read: unrestricted, Write: unrestricted
  [31] MCSPI1_CS1_WAKEUPEVENT ro — Pad_x wake-up event status latched in the IO
    0=MCSPI1_CS1_WAKEUPEVENT_0_r (No wake-up event occurred); 1=MCSPI1_CS1_WAKEUPEVENT_1_r (A wake-up event occurred)
  [30] MCSPI1_CS1_WAKEUPENABLE rw — Input pad wake-up enable (and OFF mode input enable value)
    values as CONTROL_CORE_PAD0_ABE_PDM_LB_CLK_PAD1_ABE_CLKS.ABE_CLKS_WAKEUPENABLE
  [29] MCSPI1_CS1_OFFMODEPULLTYPESELECT rw — OffMode mode pullup/down selection for pad mcspi1_cs1
    0=Offmode pulldown selected; 1=Offmode pullup selected
  [28] MCSPI1_CS1_OFFMODEPULLUDENABLE rw — OffMode mode pullup/down enable for pad mcspi1_cs1
    values as CONTROL_CORE_PAD0_ABE_PDM_LB_CLK_PAD1_ABE_CLKS.ABE_CLKS_OFFMODEPULLUDENABLE
  [27] MCSPI1_CS1_OFFMODEOUTVALUE rw — OffMode mode output value for pad mcspi1_cs1
    0=Set value at 0; 1=Set value at 1
  [26] MCSPI1_CS1_OFFMODEOUTENABLE rw — OffMode mode output enable value for pad mcspi1_cs1. This is an active low signal
    0=Output enable; 1=Output disable
  [25] MCSPI1_CS1_OFFMODEENABLE rw — OffMode mode override control for pad mcspi1_cs1
    values as CONTROL_CORE_PAD0_ABE_PDM_LB_CLK_PAD1_ABE_CLKS.ABE_CLKS_OFFMODEENABLE
  [24] MCSPI1_CS1_INPUTENABLE rw — Input enable value for pad mcspi1_cs1
    values as CONTROL_CORE_PAD0_ABE_PDM_LB_CLK_PAD1_ABE_CLKS.ABE_CLKS_INPUTENABLE
  [20] MCSPI1_CS1_PULLTYPESELECT rw — pullup/down selection for pad mcspi1_cs1
    0=pulldown selected; 1=pullup selected
  [19] MCSPI1_CS1_PULLUDENABLE rw — pullup/down enable for pad mcspi1_cs1
    0=pullup/down disabled; 1=pullup/down enabled
  [18:16] MCSPI1_CS1_MUXMODE rw — Functional multiplexing selection for pad mcspi1_cs1
    0=Select mcspi1_cs1; 1=Select uart1_rx; 3=Select gpio_138; 7=Select safe_mode
  [15] MCSPI1_CS0_WAKEUPEVENT ro — Pad_x wake-up event status latched in the IO
    0=MCSPI1_CS0_WAKEUPEVENT_0_r (No wake-up event occurred); 1=MCSPI1_CS0_WAKEUPEVENT_1_r (A wake-up event occurred)
  [14] MCSPI1_CS0_WAKEUPENABLE rw — Input pad wake-up enable (and OFF mode input enable value)
    values as CONTROL_CORE_PAD0_ABE_PDM_LB_CLK_PAD1_ABE_CLKS.ABE_CLKS_WAKEUPENABLE
  [13] MCSPI1_CS0_OFFMODEPULLTYPESELECT rw — OffMode mode pullup/down selection for pad mcspi1_cs0
    0=Offmode pulldown selected; 1=Offmode pullup selected
  [12] MCSPI1_CS0_OFFMODEPULLUDENABLE rw — OffMode mode pullup/down enable for pad mcspi1_cs0
    values as CONTROL_CORE_PAD0_ABE_PDM_LB_CLK_PAD1_ABE_CLKS.ABE_CLKS_OFFMODEPULLUDENABLE
  [11] MCSPI1_CS0_OFFMODEOUTVALUE rw — OffMode mode output value for pad mcspi1_cs0
    0=Set value at 0; 1=Set value at 1
  [10] MCSPI1_CS0_OFFMODEOUTENABLE rw — OffMode mode output enable value for pad mcspi1_cs0. This is an active low signal
    0=Output enable; 1=Output disable
  [9] MCSPI1_CS0_OFFMODEENABLE rw — OffMode mode override control for pad mcspi1_cs0
    values as CONTROL_CORE_PAD0_ABE_PDM_LB_CLK_PAD1_ABE_CLKS.ABE_CLKS_OFFMODEENABLE
  [8] MCSPI1_CS0_INPUTENABLE rw — Input enable value for pad mcspi1_cs0
    values as CONTROL_CORE_PAD0_ABE_PDM_LB_CLK_PAD1_ABE_CLKS.ABE_CLKS_INPUTENABLE
  [4] MCSPI1_CS0_PULLTYPESELECT rw — pullup/down selection for pad mcspi1_cs0
    0=pulldown selected; 1=pullup selected
  [3] MCSPI1_CS0_PULLUDENABLE rw — pullup/down enable for pad mcspi1_cs0
    0=pullup/down disabled; 1=pullup/down enabled
  [2:0] MCSPI1_CS0_MUXMODE rw — Functional multiplexing selection for pad mcspi1_cs0
    0=Select mcspi1_cs0; 3=Select gpio_137; 7=Select safe_mode
